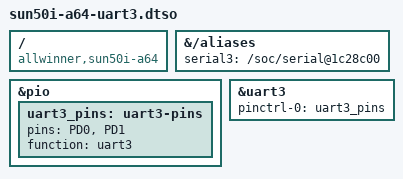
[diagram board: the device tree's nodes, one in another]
/dts-v1/;
/plugin/;

/ {
	compatible = "allwinner,sun50i-a64";

	fragment@0 {
		target-path = "/aliases";
		__overlay__ {
			serial3 = "/soc/serial@1c28c00";
		};
	};

	fragment@1 {
		target = <&pio>;
		__overlay__ {
			uart3_pins: uart3-pins {
				pins = "PD0", "PD1";
				function = "uart3";
			};
		};
	};

	fragment@2 {
		target = <&uart3>;
		 __overlay__ {
			pinctrl-names = "default";
			pinctrl-0 = <&uart3_pins>;
			status = "okay";
		};
	};
};
